# liliumSOC1_application register map
Vendor: Nordic Semiconductor; Series: liliumSOC1; File version: 1
CPU: CM33 r0p4, little endian, MPU, FPU, 3 interrupt priority bits, 480 interrupts
Registers are 32-bit, read-write, reset 0x0 unless marked. A register's access mark holds for its fields unless they carry their own. Offsets are from the block's base; [hi:lo] are bit positions; lines under a group give offsets from that group; {n}, {i} and the like mark numbered series; 'fields as' and 'values as' point back to an identical list.

## ICACHEDATA_S — CACHEDATA 0
Base 0x12F00000
Same registers: DCACHEDATA_S 0x32F00000
{0x0+0x40*i} SET[{i}] (i=0..255) group — Unspecified
  {0x0+0x20*j} WAY[{j}] (j=0..1) group — Unspecified
    {0x0+8k} DU[{k}] (k=0..3) group — Unspecified
      {0x0+4l} DATA[{l}] (l=0..1) — Description collection: Cache data bits for DATA[q] in DU[p] (DataUnit) of SET[n], WAY[o].
        [31:0] Data ro

## ICACHEINFO_S — CACHEINFO 0
Base 0x12F10000
Same registers: DCACHEINFO_S 0x32F10000
{0x0+8i} SET[{i}] (i=0..255) group — Unspecified
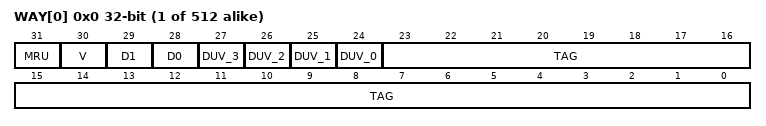
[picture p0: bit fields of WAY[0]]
  {0x0+4j} WAY[{j}] (j=0..1) — Description collection: Cache information for SET[n], WAY[o].
    [31] MRU ro — Most recently used way.
      0=Way0 was most recently used; 1=Way1 was most recently used
    [30] V ro — Line valid bit.
      0=Invalid cache line; 1=Valid cache line
    [29] D1 ro — Dirty data unit 1.
      0=Clean data unit; 1=Dirty data unit
    [28] D0 ro — Dirty data unit 0.
      0=Clean data unit; 1=Dirty data unit
    [n+24] DUV_{n} ro (n=0..3) — Data unit valid info.
      0=Invalid data unit; 1=Valid data unit
    [23:0] TAG ro — Cache tag.

## GLOBAL_STMDATA_NS — System Trace Macrocell data buffer 0
Base 0xA0000000
Same registers: GLOBAL_STMDATA_S 0xA0000000 (alternate view of GLOBAL_STMDATA_NS)
{0x0+0x2000000*i} DOMAIN[{i}] (i=0..15) group — Unspecified
  {0x0+j} NSDATA[{j}] (j=0..16777215) 8-bit — Description collection: NonSecure STM output data buffer for domain n. Writes to this region generates trace packets with id n+96.
  {0x1000000+j} SDATA[{j}] (j=0..16777215) 8-bit — Description collection: Secure STM output data buffer for domain n. Writes to this region generates trace packets with id n+32.
{0x0+0x1000000*i} BUFFER[{i}] (i=0..15) group (alternate view of DOMAIN[{i}]) — Raw buffer access to STM array. Use when DOMAIN array does not apply.
  {0x0+j} DATA[{j}] (j=0..16777215) 8-bit — Description collection: STM output data buffer n. Writes to this region generates trace packets.

## GLOBAL_TDDCONF_NS — TDDCONF 0
Base 0xBF001000
Same registers: GLOBAL_TDDCONF_S 0xBF001000 (alternate view of GLOBAL_TDDCONF_NS)
0x400 SYSPWRUPREQ — System power-up request
  [0] ACTIVE — Activate power-up request
    0=NotActive (Power-up request not active); 1=Active (Power-up request active)
0x404 DBGPWRUPREQ — Debug power-up request
  fields as SYSPWRUPREQ
0x408 TRACEPORTSPEED — Trace port trace clock speed
  [1:0] SPEED — Trace clock speed
    0=Speed25MHz; 1=Speed12500KHz (Speed 12.5MHz); 2=Speed6250KHz (Speed 6.25MHz); 3=Speed3125KHz (Speed 3.125MHz)
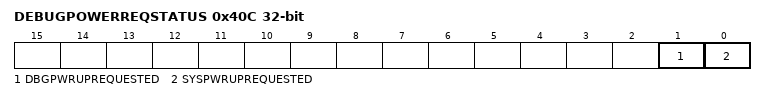
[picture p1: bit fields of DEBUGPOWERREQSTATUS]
0x40C DEBUGPOWERREQSTATUS ro — Combined effective system status of both SWJ-DP and TDDCONF registers originated power requests
  [1] DBGPWRUPREQUESTED — Debug domain powerup request status
    0=NoPowerReq (Power not requested); 1=Power requested
  [0] SYSPWRUPREQUESTED — System powerup request status
    0=NoPowerReq (Power not requested); 1=Power requested

## GLOBAL_TSGEN_NS — GENERIC
Base 0xBF041000
Same registers: GLOBAL_ETB_NS 0xBF044000, GLOBAL_ETR_NS 0xBF045000
0x00 TASKS_GENERICTASK wo — Generic event
  [0] TASKS_GENERICTASK
    1=Trigger task
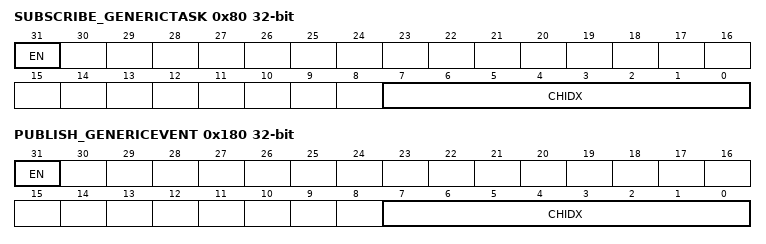
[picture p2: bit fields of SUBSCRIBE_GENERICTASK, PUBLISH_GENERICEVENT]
0x80 SUBSCRIBE_GENERICTASK — Subscribe configuration for task GENERICTASK
  [31] EN
    0=Disabled (Disable subscription); 1=Enabled (Enable subscription)
  [7:0] CHIDX — DPPI channel that task GENERICTASK will subscribe to
0x100 EVENTS_GENERICEVENT — Generic event
  [0] EVENTS_GENERICEVENT
    0=NotGenerated (Event not generated); 1=Generated (Event generated)
0x180 PUBLISH_GENERICEVENT — Publish configuration for event GENERICEVENT
  [31] EN
    0=Disabled (Disable publishing); 1=Enabled (Enable publishing)
  [7:0] CHIDX — DPPI channel that event GENERICEVENT will publish to
0x300 INTEN — Enable or disable interrupt
  [0] GENERICEVENT — Enable or disable interrupt for event GENERICEVENT
    0=Disabled; 1=Enabled
0x304 INTENSET — Enable interrupt
  [0] GENERICEVENT — Write '1' to enable interrupt for event GENERICEVENT
    on read: 0=Disabled (Read: Disabled); 1=Enabled (Read: Enabled) | on write: 1=Set (Enable)
0x308 INTENCLR — Disable interrupt
  [0] GENERICEVENT — Write '1' to disable interrupt for event GENERICEVENT
    on read: 0=Disabled (Read: Disabled); 1=Enabled (Read: Enabled) | on write: 1=Clear (Disable)
